# XHSC_HC32F002 register map
Vendor: XHSC Co.Ltd; Series: ARMCM0P; File version: 1.0
CPU: CM0P r0p0, little endian, no MPU, no FPU, 3 interrupt priority bits
Registers are 32-bit, read-write, reset 0x0 unless marked. A register's access mark holds for its fields unless they carry their own. Offsets are from the block's base; lines under a group give offsets from that group; [hi:lo] are bit positions; {n}, {i} and the like mark numbered series; 'fields as' and 'values as' point back to an identical list; <NAME> marks a mode.

## Memory map
0x40000000 LPUART0 size 0x1C — desc LPUART
0x40000400 I2C size 0x44
0x40000800 SPI size 0x28
0x40000F80 IWDT size 0x14
0x40002000 SYSCTRL size 0x804
0x40002400 ADC size 0xD0
0x40002680 LVD size 0xB0
0x40004000 LPUART1 size 0x1C — desc LPUART
0x40005000 CTRIM size 0x44
0x40005800 ATIM3MODE0 size 0x34
0x40005800 ATIM3MODE1 size 0x40
0x40005800 ATIM3MODE23 size 0x5C
0x40006800 WWDT size 0xC
0x40007400 BTIM3 size 0x76 — desc BTIM
0x40007400 GTIM size 0x780
0x40007500 BTIM4 size 0x76 — desc BTIM
0x40007600 BTIM5 size 0x76 — desc BTIM
0x40020000 FLASH size 0x88
0x40020C00 GPIOA size 0xB0 — desc GPIO
0x40020CA0 GPIOAUX size 0x180
0x40020D00 GPIOB size 0xB0 — desc GPIO
0x40020E00 GPIOC size 0xB0 — desc GPIO
0x40020F00 GPIOD size 0xB0 — desc GPIO

## ADC
Base 0x40002400
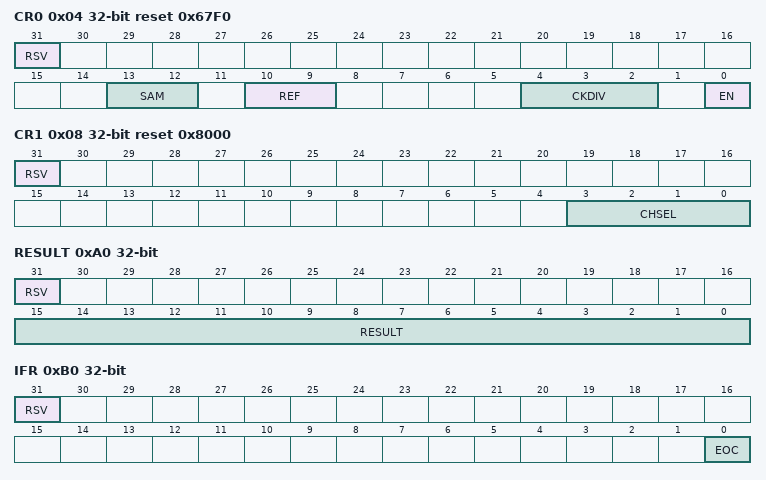
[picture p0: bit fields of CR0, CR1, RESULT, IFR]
0x04 CR0 reset 0x67F0 (reset mask 0xBFFF)
  [31] RSV, [13:12] SAM, [10:9] REF, [4:2] CKDIV, [0] EN
0x08 CR1 reset 0x8000 (reset mask 0xFFFC)
  [31] RSV, [3:0] CHSEL
0xA0 RESULT ro (reset mask 0xFFF)
  [31] RSV, [15:0] RESULT
0xB0 IFR ro (reset mask 0x3F)
  [31] RSV, [0] EOC
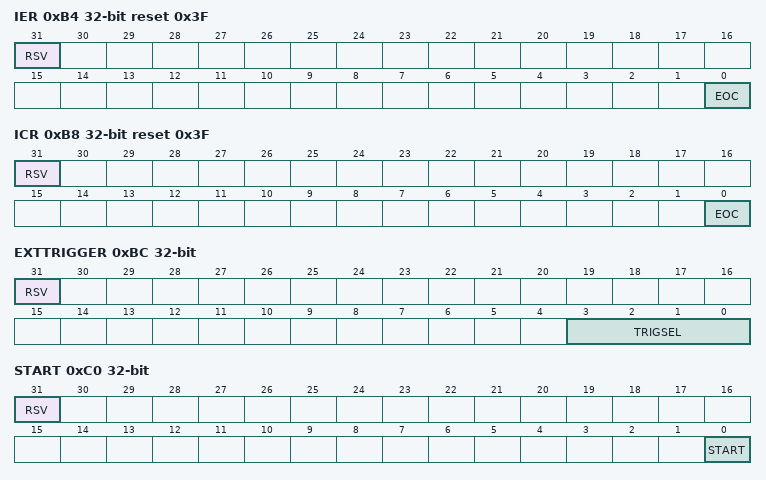
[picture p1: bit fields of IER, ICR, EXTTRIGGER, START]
0xB4 IER reset 0x3F (reset mask 0x3F)
  [31] RSV, [0] EOC
0xB8 ICR reset 0x3F (reset mask 0x3F)
  [31] RSV, [0] EOC
0xBC EXTTRIGGER
  [31] RSV, [3:0] TRIGSEL
0xC0 START wo (reset mask 0x1)
  [31] RSV, [0] START
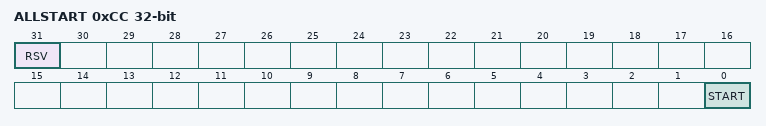
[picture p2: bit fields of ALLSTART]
0xCC ALLSTART (reset mask 0x1)
  [31] RSV, [0] START

## ATIM3MODE0
Base 0x40005800
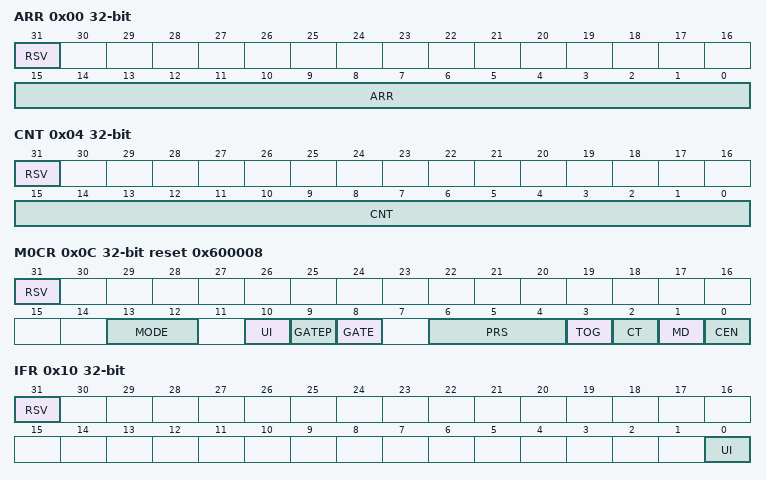
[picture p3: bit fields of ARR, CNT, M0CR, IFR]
0x00 ARR (reset mask 0xFFFF)
  [31] RSV, [15:0] ARR
0x04 CNT (reset mask 0xFFFF)
  [31] RSV, [15:0] CNT
0x08 CNT32
0x0C M0CR reset 0x600008 (reset mask 0x377F)
  [31] RSV, [13:12] MODE, [10] UI, [9] GATEP, [8] GATE, [6:4] PRS, [3] TOG, [2] CT, [1] MD, [0] CEN
0x10 IFR ro (reset mask 0x1)
  [31] RSV, [0] UI
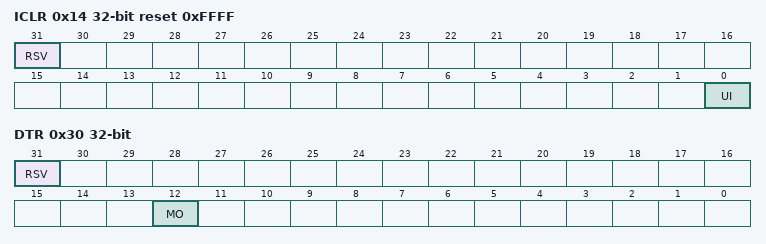
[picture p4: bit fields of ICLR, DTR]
0x14 ICLR reset 0xFFFF (reset mask 0x1)
  [31] RSV, [0] UI
0x30 DTR (reset mask 0x1000)
  [31] RSV, [12] MO

## ATIM3MODE1
Base 0x40005800; alternate view of ATIM3MODE0
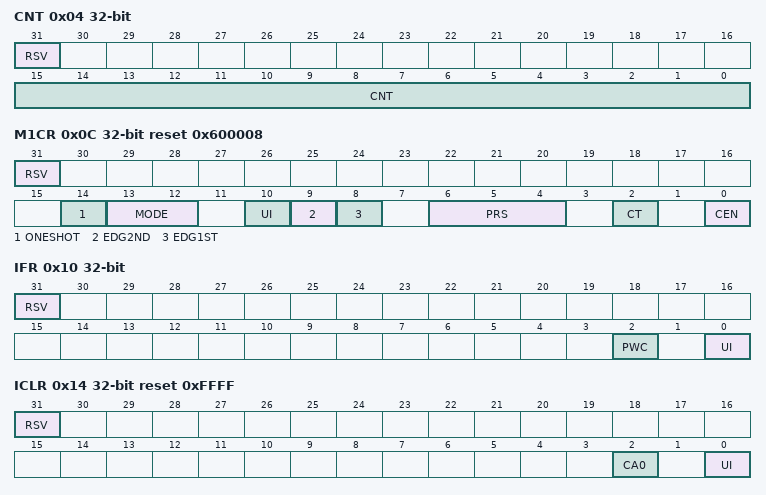
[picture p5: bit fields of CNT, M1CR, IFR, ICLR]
0x04 CNT (reset mask 0xFFFF)
  [31] RSV, [15:0] CNT
0x0C M1CR reset 0x600008 (reset mask 0x7775)
  [31] RSV, [14] ONESHOT, [13:12] MODE, [10] UI, [9] EDG2ND, [8] EDG1ST, [6:4] PRS, [2] CT, [0] CEN
0x10 IFR ro (reset mask 0x5)
  [31] RSV, [2] PWC, [0] UI
0x14 ICLR reset 0xFFFF (reset mask 0x5)
  [31] RSV, [2] CA0, [0] UI
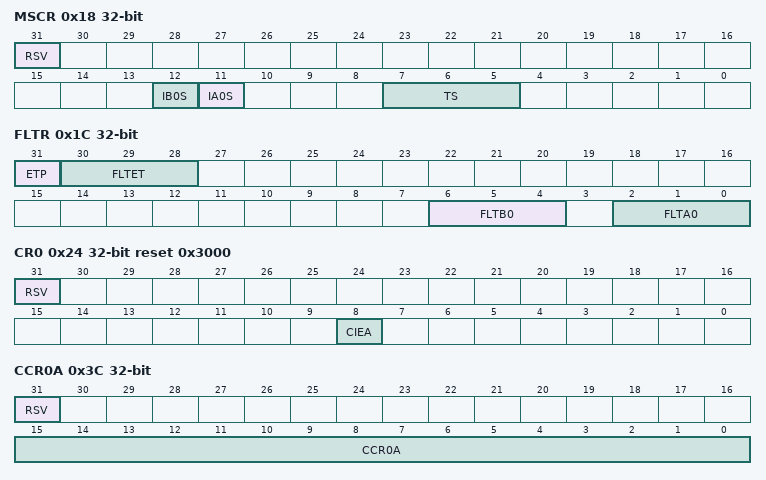
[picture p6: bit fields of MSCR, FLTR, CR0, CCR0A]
0x18 MSCR (reset mask 0x18E0)
  [31] RSV, [12] IB0S, [11] IA0S, [7:5] TS
0x1C FLTR
  [31] ETP, [30:28] FLTET, [6:4] FLTB0, [2:0] FLTA0
0x24 CR0 reset 0x3000 (reset mask 0x100)
  [31] RSV, [8] CIEA
0x3C CCR0A ro (reset mask 0xFFFF)
  [31] RSV, [15:0] CCR0A

## ATIM3MODE23
Base 0x40005800; alternate view of ATIM3MODE0
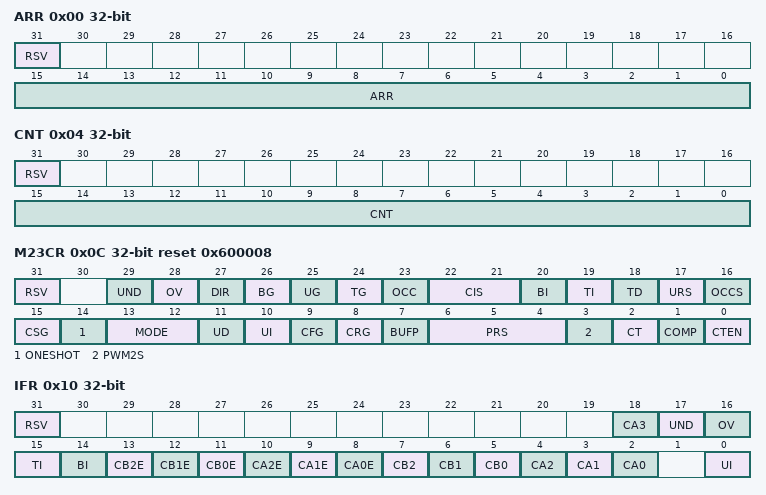
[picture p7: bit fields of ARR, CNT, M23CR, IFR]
0x00 ARR (reset mask 0xFFFF)
  [31] RSV, [15:0] ARR
0x04 CNT (reset mask 0xFFFF)
  [31] RSV, [15:0] CNT
0x0C M23CR reset 0x600008 (reset mask 0xFFFFFFF)
  [31] RSV, [29] UND, [28] OV, [27] DIR, [26] BG wo, [25] UG wo, [24] TG wo, [23] OCC, [22:21] CIS, [20] BI, [19] TI, [18] TD, [17] URS, [16] OCCS, [15] CSG, [14] ONESHOT, [13:12] MODE, [11] UD, [10] UI, [9] CFG, [8] CRG, [7] BUFP, [6:4] PRS, [3] PWM2S, [2] CT, [1] COMP, [0] CTEN
0x10 IFR ro (reset mask 0xFFFD)
  [31] RSV, [18] CA3, [17] UND, [16] OV, [15] TI, [14] BI, [13] CB2E, [12] CB1E, [11] CB0E, [10] CA2E, [9] CA1E, [8] CA0E, [7] CB2, [6] CB1, [5] CB0, [4] CA2, [3] CA1, [2] CA0, [0] UI
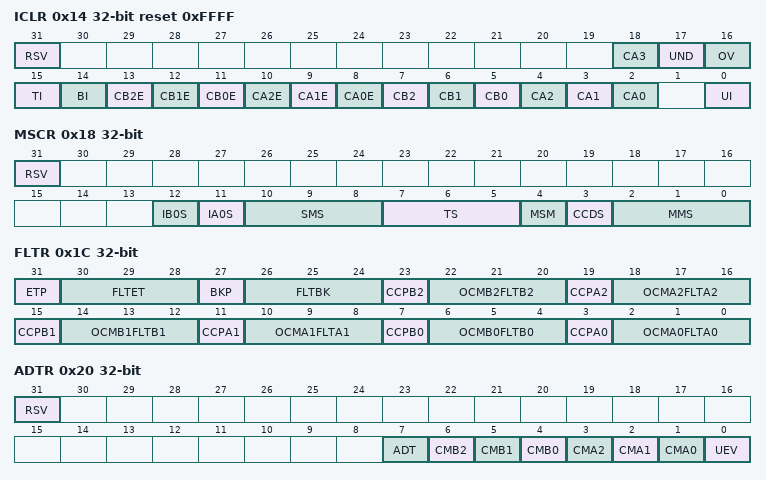
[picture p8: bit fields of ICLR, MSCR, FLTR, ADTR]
0x14 ICLR wo reset 0xFFFF (reset mask 0xFFFD)
  [31] RSV rw, [18] CA3 rw, [17] UND rw, [16] OV rw, [15] TI rw, [14] BI rw, [13] CB2E rw, [12] CB1E rw, [11] CB0E rw, [10] CA2E rw, [9] CA1E rw, [8] CA0E rw, [7] CB2 rw, [6] CB1 rw, [5] CB0 rw, [4] CA2 rw, [3] CA1 rw, [2] CA0 rw, [0] UI rw
0x18 MSCR (reset mask 0x1FFF)
  [31] RSV, [12] IB0S, [11] IA0S, [10:8] SMS, [7:5] TS, [4] MSM, [3] CCDS, [2:0] MMS
0x1C FLTR
  [31] ETP, [30:28] FLTET, [27] BKP, [26:24] FLTBK, [23] CCPB2, [22:20] OCMB2FLTB2, [19] CCPA2, [18:16] OCMA2FLTA2, [15] CCPB1, [14:12] OCMB1FLTB1, [11] CCPA1, [10:8] OCMA1FLTA1, [7] CCPB0, [6:4] OCMB0FLTB0, [3] CCPA0, [2:0] OCMA0FLTA0
0x20 ADTR (reset mask 0xFF)
  [31] RSV, [7] ADT, [6] CMB2, [5] CMB1, [4] CMB0, [3] CMA2, [2] CMA1, [1] CMA0, [0] UEV
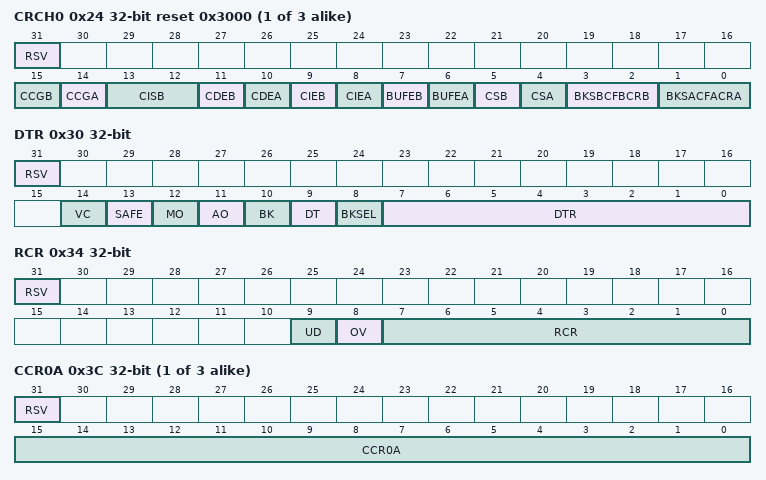
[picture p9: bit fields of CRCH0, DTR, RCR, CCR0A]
{0x24+4i} CRCH{i} reset 0x3000 (reset mask 0xFFFF) (i=0..2)
  [31] RSV, [15] CCGB, [14] CCGA, [13:12] CISB, [11] CDEB, [10] CDEA, [9] CIEB, [8] CIEA, [7] BUFEB, [6] BUFEA, [5] CSB, [4] CSA, [3:2] BKSBCFBCRB, [1:0] BKSACFACRA
0x30 DTR (reset mask 0xFFFF)
  [31] RSV, [14] VC, [13] SAFE, [12] MO, [11] AO, [10] BK, [9] DT, [8] BKSEL, [7:0] DTR
0x34 RCR (reset mask 0xFF)
  [31] RSV, [9] UD, [8] OV, [7:0] RCR
{0x3C+8i} CCR{i}A (reset mask 0xFFFF) (i=0..2)
  [31] RSV, [15:0] CCR{i}A
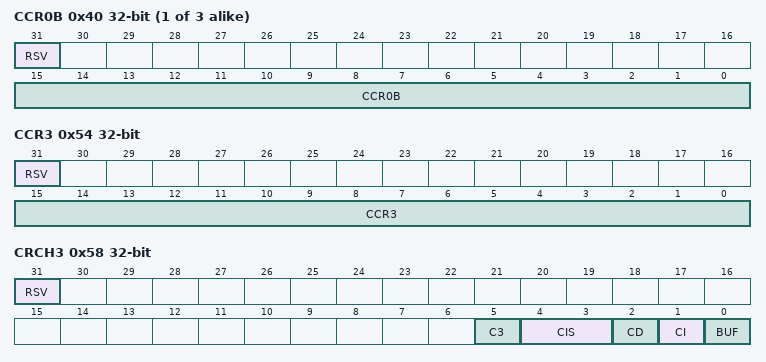
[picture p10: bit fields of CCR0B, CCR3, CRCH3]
{0x40+8i} CCR{i}B (reset mask 0xFFFF) (i=0..2)
  [31] RSV, [15:0] CCR{i}B
0x54 CCR3 (reset mask 0xFFFF)
  [31] RSV, [15:0] CCR3
0x58 CRCH3 (reset mask 0xFFFF)
  [31] RSV, [5] C3, [4:3] CIS, [2] CD, [1] CI, [0] BUF
